# CY8C5868AXI_LP035 register map
File version: 0.1
CY8C58LP
Registers are 8-bit, read-write, no defined reset value unless marked. A register's access mark holds for its fields unless they carry their own. Offsets are from the block's base; lines under a group give offsets from that group; [hi:lo] are bit positions; {n}, {i} and the like mark numbered series; 'fields as' and 'values as' point back to an identical list; <NAME> marks a mode.

## Memory map
0x00000000 XBee_UART — UART
0x00000000 Timer_periode
0x00000000 PWM_Back
0x00000000 PWM_Front
0x00000000 V_seuil
0x00000000 Ampli_Recept
0x00000000 Timer_US
0x00000000 Detect_Seuil_Recept
0x00000000 US_40kHz
0x00000000 Counter_1
0x40006472 ctrl_moteur
0x40006475 ctrl_led
0x40006574 Control_Reg_1

## ctrl_moteur
Base 0x40006472
0x00 ctrl_moteur_CONTROL_REG

## ctrl_led
Base 0x40006475
Registers as ctrl_moteur (with ctrl_moteur read as ctrl_led).

## Control_Reg_1
Base 0x40006574
Registers as ctrl_moteur (with ctrl_moteur read as Control_Reg_1).

## XBee_UART — UART
Base 0x00000000
0x4000642E RX_XBee_UART_RX_ADDRESS1 — RX Address1 Register
0x4000643E RX_XBee_UART_RX_ADDRESS2 — RX Address2 Register
0x4000644E RX_XBee_UART_RX_DATA — RX Data Register
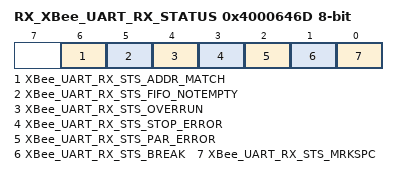
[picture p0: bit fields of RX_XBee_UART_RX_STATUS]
0x4000646D RX_XBee_UART_RX_STATUS — RX status register
  [6] XBee_UART_RX_STS_ADDR_MATCH ro, [5] XBee_UART_RX_STS_FIFO_NOTEMPTY ro, [4] XBee_UART_RX_STS_OVERRUN ro, [3] XBee_UART_RX_STS_STOP_ERROR ro, [2] XBee_UART_RX_STS_PAR_ERROR ro, [1] XBee_UART_RX_STS_BREAK ro, [0] XBee_UART_RX_STS_MRKSPC ro

## Timer_periode
Base 0x00000000
0x40006402 Timer_periode_COUNTER 24-bit — UDB.A0 - Current Down Counter Value
0x40006422 Timer_periode_PERIOD 24-bit — UDB.D0 - Assigned Period
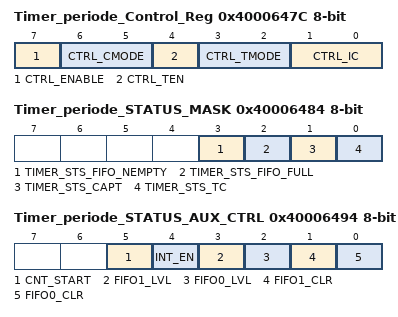
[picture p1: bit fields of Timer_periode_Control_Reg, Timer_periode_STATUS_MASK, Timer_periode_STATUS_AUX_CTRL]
0x4000647C Timer_periode_Control_Reg — UDB Control Register - Assigned Control Register Value
  [7] CTRL_ENABLE — Enable the Timer
  [6:5] CTRL_CMODE — Capture Mode
  [4] CTRL_TEN — Trigger Enable Bit
  [3:2] CTRL_TMODE — Trigger Mode
  [1:0] CTRL_IC — Interrupt Count
0x40006484 Timer_periode_STATUS_MASK — UDB Status bits Interrupt Mask Enable Register
  [3] TIMER_STS_FIFO_NEMPTY ro — FIFO Empty status
  [2] TIMER_STS_FIFO_FULL ro — FIFO Full Status
  [1] TIMER_STS_CAPT ro — Enables the Interrupt on Capture
  [0] TIMER_STS_TC ro — Enables the Interrupt on TC
0x40006494 Timer_periode_STATUS_AUX_CTRL — UDB Auxilliary Control Register
  [5] CNT_START — FIFO0 clear
    0=E_CNT_START0 (Disable counter); 1=E_CNT_START1 (Enable counter)
  [4] INT_EN
    0=E_INT_EN0 (Interrupt disabled); 1=E_INT_EN1 (Interrupt enabled)
  [3] FIFO1_LVL — FIFO level
    0=E_FIFO_LVL_0 (FIFO LVL: input mode: FIFO not full; output mode: FIFO not empty); 1=E_FIFO_LVL_1 (FIFO LVL: input mode: FIFO at least 1/2 empty; output mode: FIFO at least 1/2 full)
  [2] FIFO0_LVL — FIFO level
    values as FIFO1_LVL
  [1] FIFO1_CLR — FIFO1 clear
    0=E_FIFO_CLR_0 (Normal FIFO operation); 1=E_FIFO_CLR_1 (Clear FIFO state)
  [0] FIFO0_CLR — FIFO0 clear
    values as FIFO1_CLR

## PWM_Back
Base 0x00000000
0x4000642F PWM_Back__COMPARE1 — UDB.D0 - Assigned Compare1 Value
0x4000643F PWM_Back__COMPARE2 — UDB.D1 - Assigned Compare2 Value
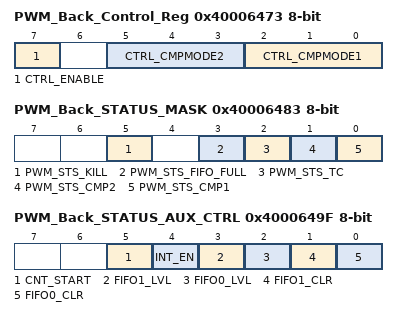
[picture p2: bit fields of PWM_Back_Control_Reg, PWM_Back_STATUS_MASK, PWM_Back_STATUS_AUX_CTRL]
0x40006473 PWM_Back_Control_Reg — UDB Control Register - Assigned Control Register Value
  [7] CTRL_ENABLE — Enable the PWM
  [5:3] CTRL_CMPMODE2 — Compare mode 2
  [2:0] CTRL_CMPMODE1 — Compare mode 1
0x40006483 PWM_Back_STATUS_MASK — UDB Status bits Interrupt Mask Enable Register
  [5] PWM_STS_KILL ro — Enables the Interrupt on Kill
  [3] PWM_STS_FIFO_FULL ro — FIFO Full Status Mask
  [2] PWM_STS_TC ro — Enables the Interrupt on Terminal Count
  [1] PWM_STS_CMP2 ro — Enables the Interrupt on Compare 2
  [0] PWM_STS_CMP1 ro — Enables the Interrupt on Compare 1
0x4000649F PWM_Back_STATUS_AUX_CTRL — UDB Auxilliary Control Register
  [5] CNT_START — FIFO0 clear
    0=E_CNT_START0 (Disable counter); 1=E_CNT_START1 (Enable counter)
  [4] INT_EN
    0=E_INT_EN0 (Interrupt disabled); 1=E_INT_EN1 (Interrupt enabled)
  [3] FIFO1_LVL — FIFO level
    0=E_FIFO_LVL_0 (FIFO LVL: input mode: FIFO not full; output mode: FIFO not empty); 1=E_FIFO_LVL_1 (FIFO LVL: input mode: FIFO at least 1/2 empty; output mode: FIFO at least 1/2 full)
  [2] FIFO0_LVL — FIFO level
    values as FIFO1_LVL
  [1] FIFO1_CLR — FIFO1 clear
    0=E_FIFO_CLR_0 (Normal FIFO operation); 1=E_FIFO_CLR_1 (Clear FIFO state)
  [0] FIFO0_CLR — FIFO0 clear
    values as FIFO1_CLR
